AUTOSAR XML (schema 00044)
standard types defined: boolean, float32, float64, sint16, sint32, sint64, sint8, uint16, uint32, uint64, uint8
package /AUTOSAR_Platform/CompuMethods
  compu method CompuMethod_boolean: 0=FALSE, 1=TRUE
package /AUTOSAR_Platform/DataConstrs
  range DataConstr_boolean: raw 0..1
  range DataConstr_float32: raw -3.4028235e+38..3.4028235e+38
  range DataConstr_float64: raw -1.7976931348623157e+308..1.7976931348623157e+308
  range DataConstr_sint16: raw -32768..32767
  range DataConstr_sint32: raw -2147483648..2147483647
  range DataConstr_sint64: raw -9223372036854775808..9223372036854775807
  range DataConstr_sint8: raw -128..127
  range DataConstr_uint16: raw 0..65535
  range DataConstr_uint32: raw 0..4294967295
  range DataConstr_uint64: raw 0..18446744073709551615
  range DataConstr_uint8: raw 0..255
package /VW/Global/PhysicalDimensions
  physical dimension PD_undefined_unit_helper_nounit
package /VW/Global/Units
  unit Unit_nounit: display-name=nounit, factor-si-to-unit=1.0, offset-si-to-unit=0, physical-dimension=PD_undefined_unit_helper_nounit
package /com/applied/arche/lights/ApplicationDataTypes
  app type ADT_boolean: category=BOOLEAN, compu {0=FALSE, 1=TRUE}
package /com/applied/arche/lights/BaseTypes
  base type BT_LeftHazardOutSignal_X_DE_ALU_L_440_PWM: category=FIXED_LENGTH, base-type-size=8, base-type-encoding=NONE
  base type BT_RightHazardOutSignal_X_DE_ALU_R_440_PWM: category=FIXED_LENGTH, base-type-size=8, base-type-encoding=NONE
  base type BT_StalkControl_X_hazard_triggered: category=FIXED_LENGTH, base-type-size=8, base-type-encoding=NONE
package /com/applied/arche/lights/CommunicationClusters
  can cluster can1_front_exterior: baudrate=500000, protocol-name=CAN, protocol-version=2.0, can-fd-baudrate=0
    can physical channel CHNL: comm-connectors=CN_can1_front_exterior
      frame HazardLightsReq_XIX_can1_front_exterior: id 0xB5, to FrontExteriorZonal, frame-length=8, can-addressing-mode=STANDARD, can-frame-rx-behavior=CAN-FD, can-frame-tx-behavior=CAN-FD
        pdu HazardLightsReq_XIX_can1_front_exterior: length=8, transmission-mode-true-timing=cyclic-timing={time-offset=0, time-period=0.0}, unused-bit-pattern=0
          signal StalkControl_X_hazard_triggered_XIX_HazardLightsReq_XIX_can1_front_exterior: start 38, 1 bit, little-endian, data-type-policy=OVERRIDE, i-signal-type=PRIMITIVE, init-value=0, base-type=BT_StalkControl_X_hazard_triggered, invalid-value=Invalid_StalkControl_X_hazard_triggered_XIX_HazardLightsReq_XIX_can1_front_exterior:1, compu {phys=raw for raw 0..1}, range phys 0..1, raw 0..1, transfer-property=PENDING, to FrontExteriorZonal
  can cluster can3_front_exterior: baudrate=500000, protocol-name=CAN, protocol-version=2.0, can-fd-baudrate=0
    can physical channel CHNL: comm-connectors=CN_can3_front_exterior
      frame LeftHazardOut_XIX_can3_front_exterior: id 0x1B7, from FrontExteriorZonal, frame-length=64, can-addressing-mode=STANDARD, can-frame-rx-behavior=CAN-FD, can-frame-tx-behavior=CAN-FD
        pdu LeftHazardOut_XIX_can3_front_exterior: length=64, transmission-mode-true-timing=cyclic-timing={time-offset=0, time-period=0.0}, unused-bit-pattern=0
          signal LeftHazardOutSignal_X_DE_ALU_L_440_PWM_XIX_LeftHazardOut_XIX_can3_front_exterior: start 336, 8 bit, little-endian, data-type-policy=OVERRIDE, i-signal-type=PRIMITIVE, init-value=0, base-type=BT_LeftHazardOutSignal_X_DE_ALU_L_440_PWM, invalid-value=Invalid_LeftHazardOutSignal_X_DE_ALU_L_440_PWM_XIX_LeftHazardOut_XIX_can3_front_exterior:1, compu {phys=raw for raw 0..255}, range phys 0..255, raw 0..255, transfer-property=PENDING
      frame RightHazardOut_XIX_can3_front_exterior: id 0x1C7, from FrontExteriorZonal, frame-length=64, can-addressing-mode=STANDARD, can-frame-rx-behavior=CAN-FD, can-frame-tx-behavior=CAN-FD
        pdu RightHazardOut_XIX_can3_front_exterior: length=64, transmission-mode-true-timing=cyclic-timing={time-offset=0, time-period=0.0}, unused-bit-pattern=0
          signal RightHazardOutSignal_X_DE_ALU_R_440_PWM_XIX_RightHazardOut_XIX_can3_front_exterior: start 336, 8 bit, little-endian, data-type-policy=OVERRIDE, i-signal-type=PRIMITIVE, init-value=0, base-type=BT_RightHazardOutSignal_X_DE_ALU_R_440_PWM, invalid-value=Invalid_RightHazardOutSignal_X_DE_ALU_R_440_PWM_XIX_RightHazardOut_XIX_can3_front_exterior:1, compu {phys=raw for raw 0..255}, range phys 0..255, raw 0..255, transfer-property=PENDING
package /com/applied/arche/lights/ConstantSpecifications
  4 x constant specification, all with value-spec=0:
    C_INIT_ADT_HazardActivate_hazard_activation
    C_INIT_ADT_StalkControl_hazard_triggered
    C_INIT_IF_ALU_L_440_PWM_DE_ALU_L_440_PWM
    C_INIT_IF_ALU_R_440_PWM_DE_ALU_R_440_PWM
package /com/applied/arche/lights/DataTypeMappingSets
  data type mapping set DTMS_FrontHazardsMaster
  data type mapping set DTMS_FrontLightControlMaster
package /com/applied/arche/lights/EcuInstances
  ecu instance FrontExteriorZonal: associated-com-i-pdu-group=[FrontExteriorZonal_XIX_can1_front_exterior_Rx, FrontExteriorZonal_XIX_can3_front_exterior_Tx], pn-reset-time=0.5, pnc-prepare-sleep-timer=0, sleep-mode-supported=true, wake-up-over-bus-supported=false
    can communication controller CT_can1_front_exterior: wake-up-by-controller-supported=true
    can communication controller CT_can3_front_exterior: wake-up-by-controller-supported=true
    can communication connector CN_can1_front_exterior: comm-controller=CT_can1_front_exterior, pnc-gateway-type=NONE
    can communication connector CN_can3_front_exterior: comm-controller=CT_can3_front_exterior, pnc-gateway-type=NONE
package /com/applied/arche/lights/ISignaliPduGroup
  i signal i pdu group FrontExteriorZonal_XIX_can1_front_exterior_Rx: communication-direction=IN, communication-mode=CAN_Receive_All, i-signal-i-pdus=HazardLightsReq_XIX_can1_front_exterior
  i signal i pdu group FrontExteriorZonal_XIX_can3_front_exterior_Tx: communication-direction=OUT, communication-mode=CAN_Transmit_All, i-signal-i-pdus=[LeftHazardOut_XIX_can3_front_exterior, RightHazardOut_XIX_can3_front_exterior]
package /com/applied/arche/lights/PortInterfaces
  4 x sender receiver interface:
    ADT_HazardActivate
      data hazard_activation
    ADT_StalkControl
      data hazard_triggered
    IF_ALU_L_440_PWM
      data DE_ALU_L_440_PWM
    IF_ALU_R_440_PWM
      data DE_ALU_R_440_PWM
package /com/applied/arche/lights/SwComponentTypes
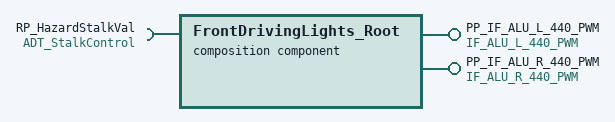
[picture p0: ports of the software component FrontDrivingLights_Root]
  composition sw component type FrontDrivingLights_Root
    provide port PP_IF_ALU_L_440_PWM: nonqueued-sender-com-spec{data-element=DE_ALU_L_440_PWM, init-value=constant-reference=C_INIT_IF_ALU_L_440_PWM_DE_ALU_L_440_PWM}, provided-interface=IF_ALU_L_440_PWM
    provide port PP_IF_ALU_R_440_PWM: nonqueued-sender-com-spec{data-element=DE_ALU_R_440_PWM, init-value=constant-reference=C_INIT_IF_ALU_R_440_PWM_DE_ALU_R_440_PWM}, provided-interface=IF_ALU_R_440_PWM
    require port RP_HazardStalkVal: nonqueued-receiver-com-spec{data-element=hazard_triggered, init-value=constant-reference=C_INIT_ADT_StalkControl_hazard_triggered}, required-interface=ADT_StalkControl
    component I_FrontHazardsMaster: type=FrontHazardsMaster
    component I_FrontLightControlMaster: type=FrontLightControlMaster
    delegate I_FrontHazardsMaster.RP_ADT_StalkControl <-> outer port RP_HazardStalkVal
    connect I_FrontHazardsMaster.PP_ADT_HazardActivate -> I_FrontLightControlMaster.RP_ADT_HazardActivate
    delegate I_FrontLightControlMaster.PP_IF_ALU_L_440_PWM <-> outer port FrontDrivingLights_Root/PP_IF_ALU_L_440_PWM
    delegate I_FrontLightControlMaster.PP_IF_ALU_R_440_PWM <-> outer port FrontDrivingLights_Root/PP_IF_ALU_R_440_PWM
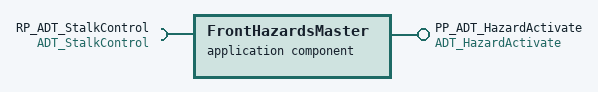
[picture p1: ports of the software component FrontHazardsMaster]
  application sw component type FrontHazardsMaster
    provide port PP_ADT_HazardActivate: nonqueued-sender-com-spec{data-element=hazard_activation, init-value=constant-reference=C_INIT_ADT_HazardActivate_hazard_activation}, provided-interface=ADT_HazardActivate
    require port RP_ADT_StalkControl: nonqueued-receiver-com-spec{data-element=hazard_triggered, init-value=constant-reference=C_INIT_ADT_StalkControl_hazard_triggered}, required-interface=ADT_StalkControl
    symbol props FrontHazardsMaster_symbol: symbol=FrontHazardsMaster
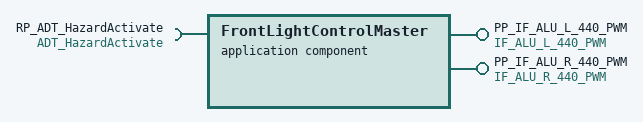
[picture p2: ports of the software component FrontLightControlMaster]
  application sw component type FrontLightControlMaster
    provide port PP_IF_ALU_L_440_PWM: nonqueued-sender-com-spec{data-element=DE_ALU_L_440_PWM, init-value=constant-reference=C_INIT_IF_ALU_L_440_PWM_DE_ALU_L_440_PWM}, provided-interface=IF_ALU_L_440_PWM
    provide port PP_IF_ALU_R_440_PWM: nonqueued-sender-com-spec{data-element=DE_ALU_R_440_PWM, init-value=constant-reference=C_INIT_IF_ALU_R_440_PWM_DE_ALU_R_440_PWM}, provided-interface=IF_ALU_R_440_PWM
    require port RP_ADT_HazardActivate: nonqueued-receiver-com-spec{data-element=hazard_activation, init-value=constant-reference=C_INIT_ADT_HazardActivate_hazard_activation}, required-interface=ADT_HazardActivate
    symbol props FrontLightControlMaster_symbol: symbol=FrontLightControlMaster
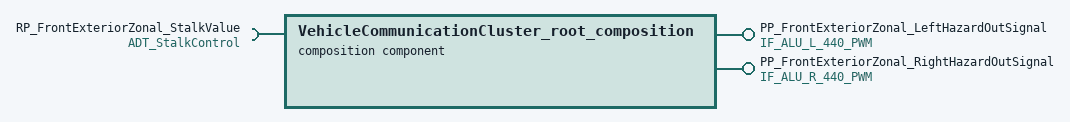
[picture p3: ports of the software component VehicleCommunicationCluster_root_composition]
  composition sw component type VehicleCommunicationCluster_root_composition
    require port RP_FrontExteriorZonal_StalkValue: nonqueued-receiver-com-spec{data-element=hazard_triggered, init-value=constant-reference=C_INIT_ADT_StalkControl_hazard_triggered}, required-interface=ADT_StalkControl
    provide port PP_FrontExteriorZonal_LeftHazardOutSignal: nonqueued-sender-com-spec{data-element=DE_ALU_L_440_PWM, init-value=constant-reference=C_INIT_IF_ALU_L_440_PWM_DE_ALU_L_440_PWM}, provided-interface=IF_ALU_L_440_PWM
    provide port PP_FrontExteriorZonal_RightHazardOutSignal: nonqueued-sender-com-spec{data-element=DE_ALU_R_440_PWM, init-value=constant-reference=C_INIT_IF_ALU_R_440_PWM_DE_ALU_R_440_PWM}, provided-interface=IF_ALU_R_440_PWM
    component I_FrontDrivingLights_Root: type=FrontDrivingLights_Root
    delegate I_FrontDrivingLights_Root.RP_HazardStalkVal <-> outer port RP_FrontExteriorZonal_StalkValue
    delegate I_FrontDrivingLights_Root.PP_IF_ALU_L_440_PWM <-> outer port PP_FrontExteriorZonal_LeftHazardOutSignal
    delegate I_FrontDrivingLights_Root.PP_IF_ALU_R_440_PWM <-> outer port PP_FrontExteriorZonal_RightHazardOutSignal
package /com/applied/arche/lights/Systems
  system SYSTEM: category=ECU_EXTRACT, pnc-vector-length=0, pnc-vector-offset=0
    system mapping VehicleCommunicationCluster_Mappings
      data-mappings:
        communication-direction=OUT, data-element=I_FrontDrivingLights_Root.VehicleCommunicationCluster_root_composition.PP_IF_ALU_L_440_PWM.DE_ALU_L_440_PWM, system-signal=LeftHazardOutSignal_X_DE_ALU_L_440_PWM
        communication-direction=OUT, data-element=I_FrontDrivingLights_Root.VehicleCommunicationCluster_root_composition.PP_IF_ALU_R_440_PWM.DE_ALU_R_440_PWM, system-signal=RightHazardOutSignal_X_DE_ALU_R_440_PWM
        communication-direction=IN, data-element=I_FrontDrivingLights_Root.VehicleCommunicationCluster_root_composition.RP_HazardStalkVal.hazard_triggered, system-signal=StalkControl_X_hazard_triggered
      sw-mappings:
        swc to ecu mapping MAPPING_FrontDrivingLights_Root: component=VehicleCommunicationCluster_root_composition.I_FrontDrivingLights_Root, ecu-instance=FrontExteriorZonal
    root-software-compositions:
      root sw composition prototype VehicleCommunicationCluster_root_composition: software-composition=VehicleCommunicationCluster_root_composition
